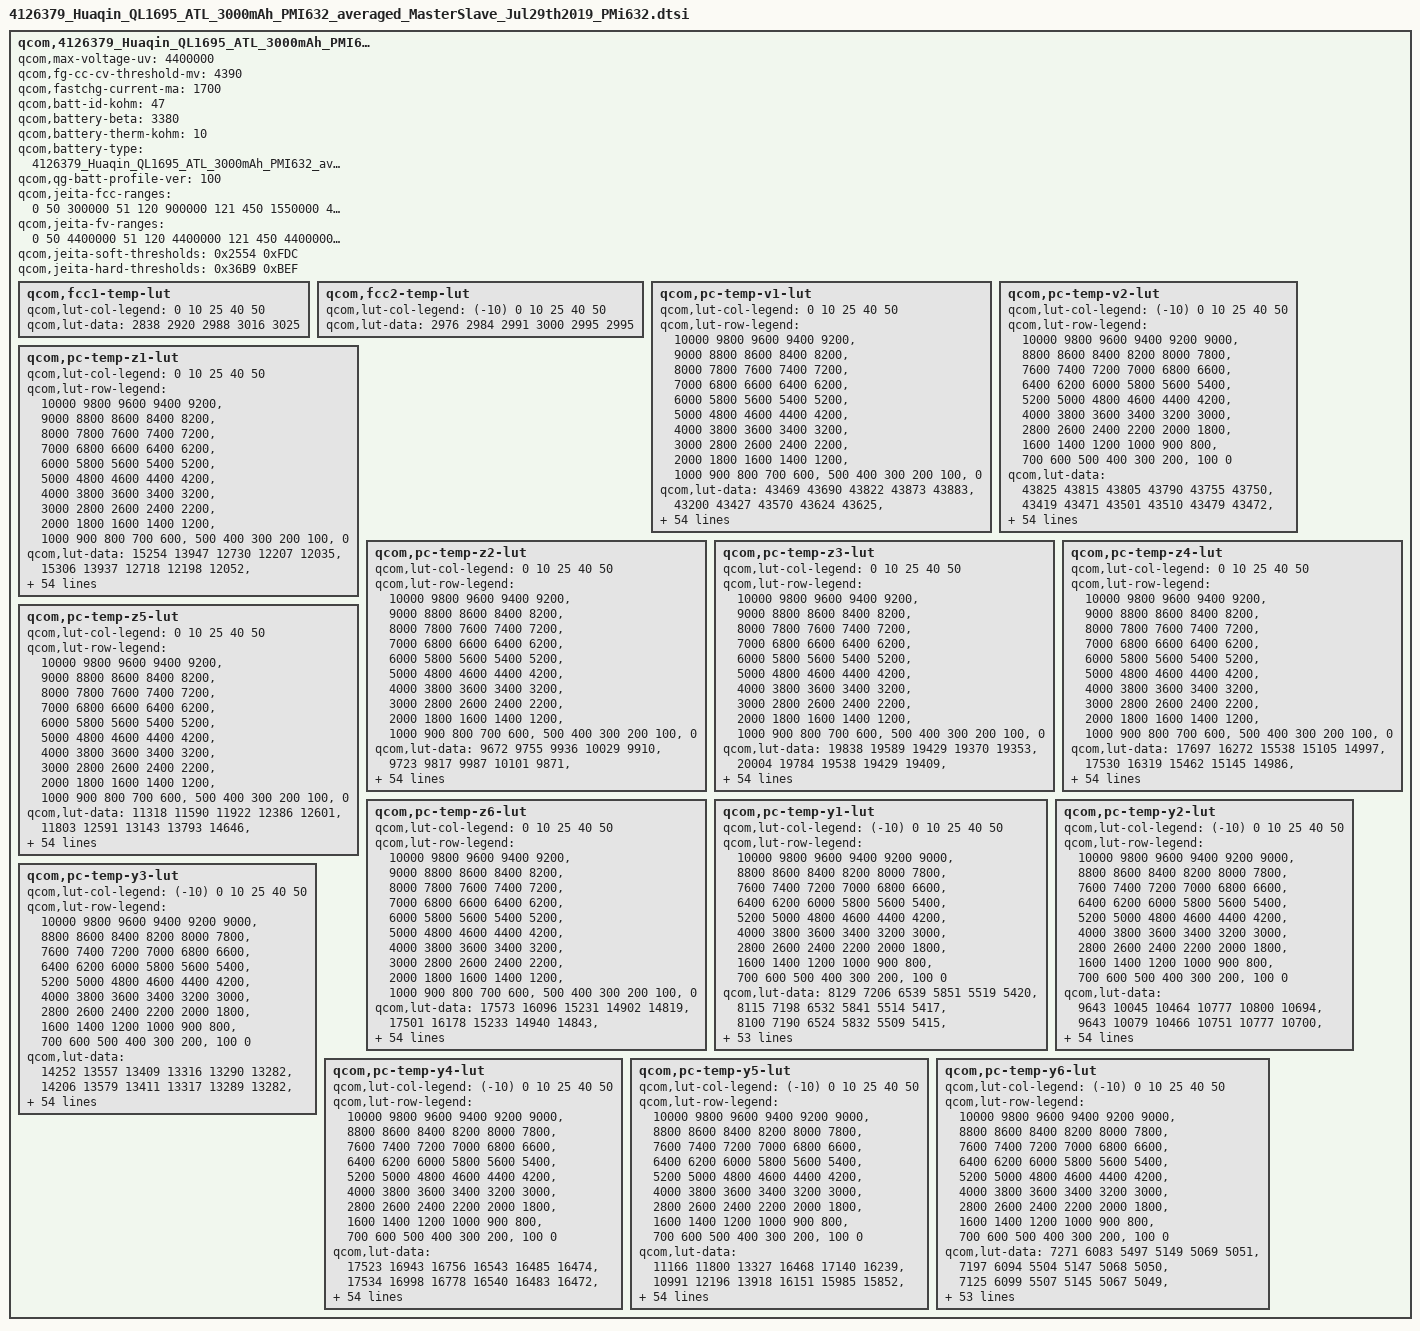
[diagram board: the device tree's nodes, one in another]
qcom,4126379_Huaqin_QL1695_ATL_3000mAh_PMI632 {
	/* 4126379_Huaqin_QL1695_ATL_3000mAh_PMI632_averaged_MasterSlave_Jul29th2019 */
	qcom,max-voltage-uv = <4400000>;
	qcom,fg-cc-cv-threshold-mv = <4390>;
	qcom,fastchg-current-ma = <1700>;
	qcom,batt-id-kohm = <47>;
	qcom,battery-beta = <3380>;
	qcom,battery-therm-kohm = <10>;
	qcom,battery-type = "4126379_Huaqin_QL1695_ATL_3000mAh_PMI632_averaged_MasterSlave_Jul29th2019";
	qcom,qg-batt-profile-ver = <100>;

	qcom,jeita-fcc-ranges = <0   50   300000
				 51   120   900000
				 121 450  1550000
				 451 550  1550000>;
	qcom,jeita-fv-ranges =  <0   50  4400000
				 51   120  4400000
				 121 450  4400000
				 451 550  4200000>;

	/* COOL = 15 DegC, WARM = 45 DegC */
	qcom,jeita-soft-thresholds = <0x2554 0xFDC>;
	/* COLD = 0 DegC, HOT = 55 DegC */
	qcom,jeita-hard-thresholds = <0x36B9 0xBEF>;

	qcom,fcc1-temp-lut {
		qcom,lut-col-legend = <0 10 25 40 50>;
		qcom,lut-data = <2838 2920 2988 3016 3025>;
	};

	qcom,fcc2-temp-lut {
		qcom,lut-col-legend = <(-10) 0 10 25 40 50>;
		qcom,lut-data = <2976 2984 2991 3000 2995 2995>;
	};

	qcom,pc-temp-v1-lut {
		qcom,lut-col-legend = <0 10 25 40 50>;
		qcom,lut-row-legend = <10000 9800 9600 9400 9200>,
			<9000 8800 8600 8400 8200>,
			<8000 7800 7600 7400 7200>,
			<7000 6800 6600 6400 6200>,
			<6000 5800 5600 5400 5200>,
			<5000 4800 4600 4400 4200>,
			<4000 3800 3600 3400 3200>,
			<3000 2800 2600 2400 2200>,
			<2000 1800 1600 1400 1200>,
			<1000 900 800 700 600>,
			<500 400 300 200 100>,
			<0>;
		qcom,lut-data = <43469 43690 43822 43873 43883>,
			<43200 43427 43570 43624 43625>,
			<42942 43177 43321 43378 43385>,
			<42697 42936 43077 43137 43148>,
			<42463 42697 42835 42899 42911>,
			<42236 42458 42595 42662 42676>,
			<42014 42223 42356 42425 42442>,
			<41798 41994 42120 42187 42209>,
			<41589 41770 41888 41954 41978>,
			<41388 41551 41661 41724 41746>,
			<41190 41338 41436 41497 41517>,
			<40993 41130 41217 41275 41295>,
			<40797 40930 41002 41055 41075>,
			<40596 40739 40796 40845 40864>,
			<40363 40545 40595 40640 40657>,
			<40126 40336 40402 40444 40458>,
			<39946 40128 40214 40254 40266>,
			<39816 39954 40035 40073 40083>,
			<39698 39815 39873 39902 39909>,
			<39567 39680 39729 39748 39753>,
			<39432 39532 39567 39588 39594>,
			<39299 39375 39354 39391 39401>,
			<39169 39201 39131 39171 39185>,
			<39043 38977 38954 38982 38993>,
			<38919 38771 38800 38819 38828>,
			<38795 38652 38672 38678 38683>,
			<38679 38568 38566 38563 38562>,
			<38575 38498 38474 38464 38458>,
			<38479 38437 38392 38373 38364>,
			<38405 38382 38319 38288 38277>,
			<38354 38330 38254 38213 38199>,
			<38313 38280 38196 38145 38127>,
			<38277 38236 38145 38085 38061>,
			<38246 38202 38100 38033 38004>,
			<38219 38173 38062 37991 37957>,
			<38193 38142 38025 37949 37909>,
			<38168 38113 37989 37902 37848>,
			<38134 38076 37951 37850 37779>,
			<38077 38014 37894 37785 37703>,
			<38000 37924 37807 37703 37624>,
			<37908 37823 37706 37608 37533>,
			<37787 37708 37593 37496 37422>,
			<37651 37572 37462 37366 37293>,
			<37497 37402 37301 37207 37135>,
			<37342 37251 37154 37065 36996>,
			<37233 37152 37058 36975 36910>,
			<37196 37121 37036 36951 36887>,
			<37167 37100 37017 36934 36873>,
			<37138 37078 36997 36919 36855>,
			<37081 37031 36953 36867 36791>,
			<36869 36807 36708 36594 36497>,
			<36418 36360 36271 36155 36054>,
			<35843 35785 35696 35578 35476>,
			<35064 35000 34911 34788 34682>,
			<33823 33761 33682 33554 33445>,
			<30000 30000 30000 30000 30000>;
	};

	qcom,pc-temp-v2-lut {
		qcom,lut-col-legend = <(-10) 0 10 25 40 50>;
		qcom,lut-row-legend = <10000 9800 9600 9400 9200 9000>,
			<8800 8600 8400 8200 8000 7800>,
			<7600 7400 7200 7000 6800 6600>,
			<6400 6200 6000 5800 5600 5400>,
			<5200 5000 4800 4600 4400 4200>,
			<4000 3800 3600 3400 3200 3000>,
			<2800 2600 2400 2200 2000 1800>,
			<1600 1400 1200 1000 900 800>,
			<700 600 500 400 300 200>,
			<100 0>;
		qcom,lut-data = <43825 43815 43805 43790 43755 43750>,
			<43419 43471 43501 43510 43479 43472>,
			<43056 43155 43215 43242 43214 43207>,
			<42740 42871 42950 42988 42963 42957>,
			<42461 42618 42704 42748 42726 42720>,
			<42214 42372 42464 42512 42492 42488>,
			<42006 42123 42221 42276 42259 42254>,
			<41813 41878 41981 42041 42026 42021>,
			<41584 41631 41749 41811 41797 41792>,
			<41299 41375 41523 41583 41570 41566>,
			<41050 41152 41304 41359 41346 41343>,
			<40904 40998 41096 41140 41126 41125>,
			<40783 40861 40895 40924 40910 40911>,
			<40565 40655 40694 40716 40704 40704>,
			<40123 40326 40493 40512 40502 40500>,
			<39712 40011 40287 40315 40309 40305>,
			<39493 39793 40066 40127 40122 40119>,
			<39328 39607 39841 39944 39943 39941>,
			<39158 39418 39626 39762 39770 39769>,
			<38982 39227 39418 39582 39610 39609>,
			<38816 39044 39222 39394 39436 39437>,
			<38659 38873 39038 39172 39214 39217>,
			<38514 38711 38867 38946 38977 38984>,
			<38395 38555 38714 38773 38793 38799>,
			<38296 38399 38578 38632 38643 38645>,
			<38213 38266 38454 38509 38516 38515>,
			<38144 38167 38340 38399 38405 38405>,
			<38084 38086 38235 38300 38307 38308>,
			<38026 38022 38137 38210 38218 38217>,
			<37968 37973 38043 38126 38136 38132>,
			<37911 37929 37963 38051 38062 38055>,
			<37856 37885 37898 37981 37994 37987>,
			<37802 37843 37845 37917 37933 37923>,
			<37744 37798 37800 37857 37868 37857>,
			<37684 37749 37764 37802 37802 37791>,
			<37622 37697 37728 37745 37730 37714>,
			<37558 37643 37688 37682 37641 37610>,
			<37493 37585 37646 37615 37544 37491>,
			<37426 37520 37591 37545 37458 37394>,
			<37359 37447 37520 37471 37383 37316>,
			<37293 37365 37435 37389 37303 37235>,
			<37229 37269 37331 37289 37206 37138>,
			<37166 37159 37211 37173 37094 37027>,
			<37096 37049 37087 37030 36952 36884>,
			<37016 36945 36959 36912 36846 36782>,
			<36917 36850 36856 36860 36802 36742>,
			<36857 36802 36828 36842 36788 36732>,
			<36786 36750 36791 36821 36770 36717>,
			<36693 36687 36739 36784 36740 36682>,
			<36555 36592 36651 36689 36637 36551>,
			<36322 36367 36389 36364 36296 36188>,
			<35934 35924 35914 35860 35792 35680>,
			<35343 35280 35269 35198 35138 35009>,
			<34432 34337 34374 34286 34224 34091>,
			<32920 32927 33035 32916 32950 32792>,
			<28595 28182 27887 28019 27977 27965>;
	};

	qcom,pc-temp-z1-lut {
		qcom,lut-col-legend = <0 10 25 40 50>;
		qcom,lut-row-legend = <10000 9800 9600 9400 9200>,
			<9000 8800 8600 8400 8200>,
			<8000 7800 7600 7400 7200>,
			<7000 6800 6600 6400 6200>,
			<6000 5800 5600 5400 5200>,
			<5000 4800 4600 4400 4200>,
			<4000 3800 3600 3400 3200>,
			<3000 2800 2600 2400 2200>,
			<2000 1800 1600 1400 1200>,
			<1000 900 800 700 600>,
			<500 400 300 200 100>,
			<0>;
		qcom,lut-data = <15254 13947 12730 12207 12035>,
			<15306 13937 12718 12198 12052>,
			<15331 13909 12706 12192 12046>,
			<15316 13856 12694 12188 12043>,
			<15233 13830 12680 12184 12039>,
			<15163 13827 12670 12180 12036>,
			<15144 13826 12662 12176 12035>,
			<15133 13826 12657 12173 12034>,
			<15132 13827 12651 12171 12033>,
			<15149 13828 12645 12168 12031>,
			<15168 13828 12641 12166 12029>,
			<15161 13828 12638 12165 12029>,
			<15125 13823 12635 12163 12030>,
			<15095 13800 12630 12163 12030>,
			<15083 13778 12620 12162 12030>,
			<15075 13768 12615 12162 12030>,
			<15074 13761 12615 12162 12029>,
			<15094 13756 12617 12162 12028>,
			<15120 13753 12619 12163 12028>,
			<15143 13755 12622 12163 12030>,
			<15167 13771 12624 12164 12032>,
			<15180 13800 12627 12165 12036>,
			<15183 13818 12631 12169 12040>,
			<15186 13827 12636 12173 12044>,
			<15191 13834 12643 12178 12049>,
			<15206 13840 12650 12182 12053>,
			<15222 13845 12658 12187 12056>,
			<15231 13849 12665 12192 12058>,
			<15239 13852 12672 12197 12061>,
			<15246 13857 12679 12202 12066>,
			<15253 13861 12685 12207 12070>,
			<15260 13865 12690 12211 12073>,
			<15268 13870 12694 12215 12076>,
			<15277 13877 12700 12218 12079>,
			<15287 13885 12708 12222 12083>,
			<15299 13894 12715 12226 12088>,
			<15313 13905 12722 12232 12092>,
			<15322 13915 12729 12239 12097>,
			<15331 13921 12736 12244 12101>,
			<15337 13927 12743 12248 12104>,
			<15336 13934 12750 12252 12107>,
			<15331 13941 12758 12256 12111>,
			<15332 13948 12765 12261 12114>,
			<15335 13955 12767 12263 12116>,
			<15330 13958 12774 12266 12117>,
			<15323 13958 12777 12269 12118>,
			<15317 13956 12779 12272 12119>,
			<15314 13955 12781 12272 12120>,
			<15316 13957 12788 12276 12125>,
			<15327 13972 12796 12284 12130>,
			<15355 13994 12811 12294 12139>,
			<15391 14028 12833 12308 12146>,
			<15417 14065 12860 12326 12165>,
			<15482 14134 12903 12351 12184>,
			<15482 14134 12903 12351 12184>,
			<15482 14134 12903 12351 12184>;
	};

	qcom,pc-temp-z2-lut {
		qcom,lut-col-legend = <0 10 25 40 50>;
		qcom,lut-row-legend = <10000 9800 9600 9400 9200>,
			<9000 8800 8600 8400 8200>,
			<8000 7800 7600 7400 7200>,
			<7000 6800 6600 6400 6200>,
			<6000 5800 5600 5400 5200>,
			<5000 4800 4600 4400 4200>,
			<4000 3800 3600 3400 3200>,
			<3000 2800 2600 2400 2200>,
			<2000 1800 1600 1400 1200>,
			<1000 900 800 700 600>,
			<500 400 300 200 100>,
			<0>;
		qcom,lut-data = <9672 9755 9936 10029 9910>,
			<9723 9817 9987 10101 9871>,
			<9759 9819 10018 10117 10012>,
			<9773 9812 10021 10120 10086>,
			<9782 9808 10018 10114 10091>,
			<9788 9806 10017 10106 10084>,
			<9790 9805 10018 10111 10057>,
			<9792 9806 10019 10125 9996>,
			<9791 9813 10024 10130 9967>,
			<9783 9819 10035 10114 9978>,
			<9770 9821 10041 10093 9992>,
			<9756 9825 10039 10070 10000>,
			<9737 9845 10037 10038 10007>,
			<9721 9913 10037 10028 10010>,
			<9708 9958 10038 10036 10013>,
			<9697 9962 10038 10046 10018>,
			<9697 9963 10038 10048 10027>,
			<9715 9960 10037 10045 10045>,
			<9734 9927 10036 10041 10055>,
			<9738 9897 10035 10034 10065>,
			<9740 9891 10034 10028 10072>,
			<9741 9884 10031 10052 10074>,
			<9742 9875 10027 10104 10074>,
			<9744 9857 10032 10124 10061>,
			<9746 9842 10052 10125 10001>,
			<9750 9844 10064 10119 9946>,
			<9754 9856 10040 10095 9938>,
			<9759 9863 10007 10056 9934>,
			<9764 9863 9996 10030 9936>,
			<9770 9862 9991 10010 9946>,
			<9776 9863 9989 10000 9957>,
			<9783 9867 9992 10008 9963>,
			<9790 9870 9998 10022 9969>,
			<9799 9876 10007 10025 9979>,
			<9808 9886 10029 10017 10004>,
			<9819 9895 10048 10011 10035>,
			<9831 9905 10056 10029 10075>,
			<9843 9915 10063 10068 10120>,
			<9855 9927 10079 10095 10129>,
			<9864 9940 10113 10118 10117>,
			<9834 9946 10132 10132 10108>,
			<9723 9950 10127 10134 10126>,
			<10252 9950 10122 10134 10149>,
			<12743 9947 10132 10144 10104>,
			<13411 9957 10142 10159 10087>,
			<12477 9972 10128 10184 10106>,
			<13615 9977 10121 10125 10082>,
			<13747 10046 10095 10118 10135>,
			<13794 10166 10097 10133 10127>,
			<13736 10176 10124 10212 10179>,
			<13116 10149 10210 10169 10012>,
			<12466 10089 10150 10108 9951>,
			<11791 10061 10115 10037 9917>,
			<10733 9999 10046 9980 9847>,
			<10733 9999 10046 9980 9847>,
			<10733 9999 10046 9980 9847>;
	};

	qcom,pc-temp-z3-lut {
		qcom,lut-col-legend = <0 10 25 40 50>;
		qcom,lut-row-legend = <10000 9800 9600 9400 9200>,
			<9000 8800 8600 8400 8200>,
			<8000 7800 7600 7400 7200>,
			<7000 6800 6600 6400 6200>,
			<6000 5800 5600 5400 5200>,
			<5000 4800 4600 4400 4200>,
			<4000 3800 3600 3400 3200>,
			<3000 2800 2600 2400 2200>,
			<2000 1800 1600 1400 1200>,
			<1000 900 800 700 600>,
			<500 400 300 200 100>,
			<0>;
		qcom,lut-data = <19838 19589 19429 19370 19353>,
			<20004 19784 19538 19429 19409>,
			<20098 19849 19603 19470 19420>,
			<20095 19887 19604 19482 19424>,
			<20023 19897 19592 19469 19421>,
			<19963 19881 19580 19453 19417>,
			<19947 19855 19568 19447 19410>,
			<19938 19832 19554 19444 19399>,
			<19936 19807 19541 19440 19393>,
			<19952 19789 19528 19430 19391>,
			<19972 19778 19521 19420 19390>,
			<19975 19769 19519 19415 19387>,
			<19966 19755 19516 19410 19381>,
			<19962 19731 19508 19404 19377>,
			<19974 19714 19491 19394 19373>,
			<19989 19712 19481 19387 19369>,
			<19987 19710 19479 19386 19368>,
			<19922 19705 19479 19386 19367>,
			<19859 19680 19477 19385 19366>,
			<19856 19659 19467 19383 19358>,
			<19866 19664 19462 19382 19350>,
			<19878 19681 19484 19387 19356>,
			<19894 19698 19513 19400 19375>,
			<19914 19718 19516 19414 19388>,
			<19932 19734 19511 19433 19396>,
			<19951 19735 19508 19445 19401>,
			<19966 19731 19521 19441 19403>,
			<19972 19729 19539 19433 19404>,
			<19975 19725 19540 19428 19403>,
			<19975 19721 19533 19426 19394>,
			<19961 19720 19525 19424 19384>,
			<19940 19719 19519 19421 19381>,
			<19923 19717 19512 19417 19379>,
			<19906 19706 19507 19412 19376>,
			<19889 19687 19500 19407 19370>,
			<19868 19677 19495 19402 19366>,
			<19844 19673 19489 19396 19365>,
			<19826 19669 19483 19390 19365>,
			<19817 19664 19478 19386 19365>,
			<19805 19657 19472 19383 19366>,
			<19742 19649 19468 19382 19366>,
			<19570 19634 19465 19383 19362>,
			<19469 19624 19462 19384 19358>,
			<19264 19620 19457 19384 19359>,
			<19257 19603 19450 19380 19362>,
			<19258 19577 19447 19373 19360>,
			<19257 19573 19431 19370 19357>,
			<19257 19516 19428 19372 19343>,
			<19257 19445 19428 19354 19339>,
			<19257 19459 19417 19347 19337>,
			<19257 19471 19398 19356 19362>,
			<19257 19490 19398 19363 19369>,
			<19257 19462 19402 19370 19371>,
			<19259 19444 19406 19378 19382>,
			<19259 19444 19406 19378 19382>,
			<19259 19444 19406 19378 19382>;
	};

	qcom,pc-temp-z4-lut {
		qcom,lut-col-legend = <0 10 25 40 50>;
		qcom,lut-row-legend = <10000 9800 9600 9400 9200>,
			<9000 8800 8600 8400 8200>,
			<8000 7800 7600 7400 7200>,
			<7000 6800 6600 6400 6200>,
			<6000 5800 5600 5400 5200>,
			<5000 4800 4600 4400 4200>,
			<4000 3800 3600 3400 3200>,
			<3000 2800 2600 2400 2200>,
			<2000 1800 1600 1400 1200>,
			<1000 900 800 700 600>,
			<500 400 300 200 100>,
			<0>;
		qcom,lut-data = <17697 16272 15538 15105 14997>,
			<17530 16319 15462 15145 14986>,
			<17330 16196 15376 15068 14948>,
			<17093 15853 15272 15009 14918>,
			<16802 15585 15149 14974 14905>,
			<16520 15409 15072 14947 14895>,
			<16264 15279 15036 14926 14885>,
			<16026 15209 15011 14909 14875>,
			<15854 15164 14985 14893 14864>,
			<15739 15130 14962 14879 14851>,
			<15644 15104 14940 14866 14837>,
			<15547 15081 14917 14852 14825>,
			<15454 15050 14897 14839 14812>,
			<15381 15009 14884 14826 14800>,
			<15331 14976 14875 14814 14788>,
			<15292 14954 14864 14801 14775>,
			<15263 14939 14841 14786 14761>,
			<15239 14927 14818 14769 14745>,
			<15216 14913 14805 14756 14734>,
			<15186 14902 14795 14743 14725>,
			<15149 14904 14793 14736 14720>,
			<15119 14915 14896 14796 14758>,
			<15096 14941 15039 14931 14863>,
			<15079 15117 15083 14971 14902>,
			<15077 15297 15103 14957 14898>,
			<15093 15299 15105 14937 14890>,
			<15115 15238 15056 14915 14875>,
			<15139 15174 14984 14889 14850>,
			<15170 15113 14945 14866 14829>,
			<15182 15055 14918 14845 14815>,
			<15167 15018 14898 14827 14801>,
			<15139 14991 14883 14812 14787>,
			<15113 14970 14870 14800 14773>,
			<15086 14952 14860 14790 14761>,
			<15061 14937 14850 14781 14751>,
			<15040 14924 14846 14777 14745>,
			<15021 14911 14848 14791 14764>,
			<15006 14903 14853 14817 14802>,
			<14994 14910 14861 14828 14812>,
			<14985 14925 14879 14831 14805>,
			<15033 14929 14889 14832 14796>,
			<15205 14902 14868 14818 14784>,
			<15292 14887 14849 14801 14775>,
			<15484 14886 14849 14810 14785>,
			<15425 14859 14836 14808 14784>,
			<15400 14832 14803 14788 14763>,
			<15384 14814 14776 14765 14744>,
			<15364 14839 14741 14726 14718>,
			<15342 14896 14709 14701 14685>,
			<15328 14871 14718 14709 14692>,
			<15333 14888 14787 14746 14710>,
			<15390 14888 14792 14742 14707>,
			<15421 14934 14789 14736 14705>,
			<15464 14973 14791 14729 14697>,
			<15464 14973 14791 14729 14697>,
			<15464 14973 14791 14729 14697>;
	};

	qcom,pc-temp-z5-lut {
		qcom,lut-col-legend = <0 10 25 40 50>;
		qcom,lut-row-legend = <10000 9800 9600 9400 9200>,
			<9000 8800 8600 8400 8200>,
			<8000 7800 7600 7400 7200>,
			<7000 6800 6600 6400 6200>,
			<6000 5800 5600 5400 5200>,
			<5000 4800 4600 4400 4200>,
			<4000 3800 3600 3400 3200>,
			<3000 2800 2600 2400 2200>,
			<2000 1800 1600 1400 1200>,
			<1000 900 800 700 600>,
			<500 400 300 200 100>,
			<0>;
		qcom,lut-data = <11318 11590 11922 12386 12601>,
			<11803 12591 13143 13793 14646>,
			<12155 13121 14060 15155 15632>,
			<12300 13485 14621 15607 16047>,
			<12369 13875 15073 15573 16143>,
			<12440 14401 15268 15534 16192>,
			<12572 14836 15300 15619 16085>,
			<12736 14969 15307 15841 15658>,
			<12835 15010 15281 15910 15441>,
			<12904 15039 15215 15676 15606>,
			<12961 15209 15226 15448 15844>,
			<13004 15432 15536 15463 15923>,
			<13083 15454 15874 15526 15863>,
			<13194 15349 15780 15528 15810>,
			<13524 15281 15314 15261 15787>,
			<13976 15488 15085 15010 15846>,
			<14060 15889 15614 15176 16243>,
			<13636 16087 16392 15695 17009>,
			<13233 16146 16708 16229 17292>,
			<13323 16224 16822 16885 17053>,
			<13818 16976 17151 17317 16654>,
			<14449 18706 19014 17040 16184>,
			<15215 19952 21151 16273 15553>,
			<16177 20807 20461 15672 15024>,
			<17273 21341 16646 15034 14486>,
			<18743 20826 14580 14631 14138>,
			<19949 18980 15053 14673 14367>,
			<20501 17927 15876 14827 14974>,
			<20949 17820 16513 15065 15248>,
			<21056 17819 17085 15597 15273>,
			<20405 18178 17703 16287 15309>,
			<19421 19513 18478 17062 15676>,
			<18804 20420 19337 17959 16477>,
			<18392 20339 20206 18828 17260>,
			<17993 20146 21208 19814 18174>,
			<17428 20225 21675 20369 18734>,
			<16772 20856 21631 19935 18513>,
			<16452 21391 21506 18944 17988>,
			<16505 21407 21117 18127 17675>,
			<16570 21263 19920 17331 17528>,
			<15918 20974 19181 16909 17351>,
			<13986 19805 19185 17072 16936>,
			<12855 18984 19176 17266 16384>,
			<10711 18645 18116 16693 15817>,
			<10625 18123 17719 15833 15743>,
			<10620 16755 18000 15447 15466>,
			<10598 16711 16868 15757 15628>,
			<10575 14187 17708 17275 15327>,
			<10565 12442 18906 16779 17274>,
			<10574 12665 17661 15688 16200>,
			<10598 12881 13950 13714 15616>,
			<10582 13118 13556 13748 15642>,
			<10548 12482 13449 13886 15362>,
			<10490 11908 13298 13974 16006>,
			<10490 11908 13298 13974 16006>,
			<10490 11908 13298 13974 16006>;
	};

	qcom,pc-temp-z6-lut {
		qcom,lut-col-legend = <0 10 25 40 50>;
		qcom,lut-row-legend = <10000 9800 9600 9400 9200>,
			<9000 8800 8600 8400 8200>,
			<8000 7800 7600 7400 7200>,
			<7000 6800 6600 6400 6200>,
			<6000 5800 5600 5400 5200>,
			<5000 4800 4600 4400 4200>,
			<4000 3800 3600 3400 3200>,
			<3000 2800 2600 2400 2200>,
			<2000 1800 1600 1400 1200>,
			<1000 900 800 700 600>,
			<500 400 300 200 100>,
			<0>;
		qcom,lut-data = <17573 16096 15231 14902 14819>,
			<17501 16178 15233 14940 14843>,
			<17393 16125 15230 14930 14832>,
			<17246 15966 15205 14918 14821>,
			<17030 15832 15136 14896 14814>,
			<16825 15730 15085 14872 14806>,
			<16665 15647 15060 14859 14798>,
			<16526 15596 15041 14849 14787>,
			<16444 15559 15021 14839 14778>,
			<16403 15532 15003 14827 14771>,
			<16370 15514 14988 14816 14765>,
			<16322 15498 14977 14806 14757>,
			<16258 15472 14966 14798 14749>,
			<16211 15431 14953 14789 14741>,
			<16192 15400 14939 14778 14733>,
			<16178 15388 14927 14768 14725>,
			<16158 15380 14916 14760 14718>,
			<16126 15370 14907 14753 14712>,
			<16099 15355 14899 14747 14705>,
			<16093 15346 14891 14741 14698>,
			<16089 15350 14889 14737 14692>,
			<16088 15366 14945 14767 14712>,
			<16092 15393 15023 14834 14769>,
			<16101 15484 15045 14859 14794>,
			<16113 15571 15054 14862 14797>,
			<16135 15574 15056 14863 14799>,
			<16159 15551 15043 14856 14795>,
			<16181 15527 15022 14839 14785>,
			<16203 15503 15007 14826 14774>,
			<16211 15479 14993 14816 14763>,
			<16203 15466 14981 14807 14753>,
			<16188 15458 14972 14799 14745>,
			<16175 15449 14964 14792 14738>,
			<16162 15437 14957 14786 14732>,
			<16150 15425 14951 14778 14724>,
			<16139 15420 14948 14774 14719>,
			<16127 15419 14948 14779 14727>,
			<16124 15418 14948 14787 14744>,
			<16125 15423 14951 14790 14748>,
			<16128 15434 14957 14791 14746>,
			<16131 15437 14961 14792 14743>,
			<16131 15426 14953 14786 14736>,
			<16131 15421 14944 14780 14730>,
			<16132 15428 14944 14785 14737>,
			<16118 15417 14936 14783 14737>,
			<16118 15399 14923 14771 14727>,
			<16114 15391 14903 14759 14718>,
			<16110 15380 14888 14744 14700>,
			<16110 15373 14876 14724 14683>,
			<16118 15380 14877 14726 14686>,
			<16145 15407 14902 14748 14710>,
			<16195 15432 14910 14754 14715>,
			<16247 15459 14918 14759 14719>,
			<16325 15500 14932 14765 14726>,
			<16325 15500 14932 14765 14726>,
			<16325 15500 14932 14765 14726>;
	};

	qcom,pc-temp-y1-lut {
		qcom,lut-col-legend = <(-10) 0 10 25 40 50>;
		qcom,lut-row-legend = <10000 9800 9600 9400 9200 9000>,
			<8800 8600 8400 8200 8000 7800>,
			<7600 7400 7200 7000 6800 6600>,
			<6400 6200 6000 5800 5600 5400>,
			<5200 5000 4800 4600 4400 4200>,
			<4000 3800 3600 3400 3200 3000>,
			<2800 2600 2400 2200 2000 1800>,
			<1600 1400 1200 1000 900 800>,
			<700 600 500 400 300 200>,
			<100 0>;
		qcom,lut-data = <8129 7206 6539 5851 5519 5420>,
			<8115 7198 6532 5841 5514 5417>,
			<8100 7190 6524 5832 5509 5415>,
			<8085 7182 6516 5824 5504 5413>,
			<8072 7176 6509 5816 5500 5411>,
			<8062 7171 6503 5808 5497 5409>,
			<8056 7167 6498 5801 5494 5408>,
			<8051 7164 6494 5794 5492 5406>,
			<8047 7158 6488 5788 5489 5405>,
			<8044 7146 6480 5783 5485 5403>,
			<8042 7138 6472 5778 5482 5402>,
			<8042 7138 6465 5773 5482 5402>,
			<8043 7139 6458 5768 5481 5402>,
			<8046 7142 6453 5763 5480 5402>,
			<8059 7155 6450 5758 5479 5401>,
			<8070 7166 6448 5755 5477 5401>,
			<8068 7164 6453 5754 5477 5401>,
			<8064 7158 6461 5754 5476 5401>,
			<8060 7156 6463 5754 5476 5401>,
			<8048 7153 6460 5752 5477 5401>,
			<8035 7151 6457 5751 5477 5401>,
			<8029 7154 6456 5752 5478 5402>,
			<8024 7160 6455 5754 5479 5404>,
			<8018 7160 6455 5756 5480 5405>,
			<8011 7153 6457 5758 5482 5406>,
			<8004 7145 6459 5761 5484 5407>,
			<7998 7141 6462 5763 5486 5409>,
			<7992 7137 6465 5766 5488 5411>,
			<7986 7133 6468 5769 5491 5414>,
			<7979 7129 6469 5772 5495 5416>,
			<7971 7125 6471 5776 5499 5418>,
			<7965 7121 6473 5782 5502 5421>,
			<7960 7118 6475 5789 5505 5424>,
			<7955 7115 6477 5795 5509 5426>,
			<7949 7110 6478 5800 5512 5428>,
			<7944 7106 6480 5804 5515 5430>,
			<7937 7101 6482 5808 5517 5431>,
			<7929 7096 6484 5812 5519 5433>,
			<7920 7090 6487 5816 5521 5435>,
			<7910 7084 6490 5820 5523 5437>,
			<7901 7078 6493 5825 5525 5439>,
			<7893 7072 6494 5832 5529 5442>,
			<7888 7068 6495 5840 5533 5444>,
			<7888 7069 6497 5849 5536 5447>,
			<7894 7073 6499 5861 5541 5451>,
			<7959 7113 6519 5871 5549 5456>,
			<8020 7134 6524 5877 5551 5457>,
			<8028 7135 6525 5882 5553 5458>,
			<8030 7136 6526 5889 5554 5457>,
			<8030 7138 6527 5896 5555 5459>,
			<8033 7142 6532 5900 5559 5463>,
			<8037 7164 6541 5922 5569 5470>,
			<8039 7187 6559 5952 5584 5480>,
			<8054 7211 6596 5990 5603 5495>,
			<8054 7211 6596 5990 5603 5495>,
			<8054 7211 6596 5990 5603 5495>;
	};

	qcom,pc-temp-y2-lut {
		qcom,lut-col-legend = <(-10) 0 10 25 40 50>;
		qcom,lut-row-legend = <10000 9800 9600 9400 9200 9000>,
			<8800 8600 8400 8200 8000 7800>,
			<7600 7400 7200 7000 6800 6600>,
			<6400 6200 6000 5800 5600 5400>,
			<5200 5000 4800 4600 4400 4200>,
			<4000 3800 3600 3400 3200 3000>,
			<2800 2600 2400 2200 2000 1800>,
			<1600 1400 1200 1000 900 800>,
			<700 600 500 400 300 200>,
			<100 0>;
		qcom,lut-data = <9643 10045 10464 10777 10800 10694>,
			<9643 10079 10466 10751 10777 10700>,
			<9643 10123 10466 10727 10744 10696>,
			<9748 10167 10464 10704 10709 10685>,
			<9890 10201 10462 10683 10680 10668>,
			<9996 10215 10459 10666 10663 10648>,
			<10065 10210 10453 10649 10654 10617>,
			<10119 10201 10444 10636 10648 10585>,
			<10183 10209 10444 10632 10646 10573>,
			<10268 10276 10449 10632 10645 10569>,
			<10316 10336 10456 10632 10645 10567>,
			<10300 10360 10462 10640 10648 10576>,
			<10268 10380 10470 10655 10655 10593>,
			<10236 10396 10488 10671 10665 10596>,
			<10126 10416 10536 10692 10685 10595>,
			<10038 10436 10572 10714 10713 10600>,
			<9935 10453 10580 10737 10749 10640>,
			<9748 10470 10584 10760 10796 10709>,
			<9690 10483 10583 10782 10849 10774>,
			<9684 10496 10573 10806 10918 10852>,
			<9678 10505 10566 10818 10956 10894>,
			<9673 10507 10579 10803 10898 10856>,
			<9668 10507 10605 10779 10803 10791>,
			<9666 10505 10620 10775 10777 10771>,
			<9665 10500 10631 10781 10777 10767>,
			<9664 10496 10638 10790 10783 10770>,
			<9664 10499 10641 10805 10800 10803>,
			<9663 10507 10644 10823 10824 10853>,
			<9662 10505 10647 10836 10839 10871>,
			<9661 10491 10650 10846 10856 10871>,
			<9660 10463 10654 10855 10868 10874>,
			<9659 10257 10657 10867 10901 10896>,
			<9659 9860 10661 10878 10952 10920>,
			<9658 9712 10660 10880 10964 10926>,
			<9657 9685 10647 10876 10960 10938>,
			<9656 9672 10629 10872 10950 10940>,
			<9656 9667 10615 10861 10921 10912>,
			<9655 9664 10599 10846 10883 10870>,
			<9655 9662 10578 10839 10869 10841>,
			<9655 9660 10545 10836 10862 10818>,
			<9655 9658 10505 10832 10853 10803>,
			<9654 9657 10459 10822 10838 10796>,
			<9654 9656 10403 10805 10828 10794>,
			<9654 9655 10347 10767 10817 10807>,
			<9654 9654 10227 10703 10785 10779>,
			<9653 9653 10177 10693 10729 10686>,
			<9653 9653 10206 10687 10724 10630>,
			<9653 9653 10051 10699 10713 10684>,
			<9653 9652 9966 10678 10753 10664>,
			<9652 9652 9940 10677 10755 10596>,
			<9652 9652 9725 10628 10649 10587>,
			<9652 9652 9675 10582 10615 10534>,
			<9651 9651 9662 10510 10588 10471>,
			<9650 9651 9657 10464 10512 10385>,
			<9650 9651 9657 10464 10512 10385>,
			<9650 9651 9657 10464 10512 10385>;
	};

	qcom,pc-temp-y3-lut {
		qcom,lut-col-legend = <(-10) 0 10 25 40 50>;
		qcom,lut-row-legend = <10000 9800 9600 9400 9200 9000>,
			<8800 8600 8400 8200 8000 7800>,
			<7600 7400 7200 7000 6800 6600>,
			<6400 6200 6000 5800 5600 5400>,
			<5200 5000 4800 4600 4400 4200>,
			<4000 3800 3600 3400 3200 3000>,
			<2800 2600 2400 2200 2000 1800>,
			<1600 1400 1200 1000 900 800>,
			<700 600 500 400 300 200>,
			<100 0>;
		qcom,lut-data = <14252 13557 13409 13316 13290 13282>,
			<14206 13579 13411 13317 13289 13282>,
			<14102 13593 13416 13318 13289 13282>,
			<13979 13601 13422 13319 13289 13282>,
			<13875 13604 13426 13320 13290 13283>,
			<13829 13605 13428 13321 13292 13284>,
			<13829 13598 13428 13321 13295 13285>,
			<13831 13586 13428 13322 13298 13286>,
			<13813 13583 13428 13323 13300 13288>,
			<13693 13590 13426 13324 13301 13290>,
			<13605 13593 13425 13324 13302 13292>,
			<13606 13560 13425 13327 13302 13294>,
			<13609 13506 13425 13331 13302 13297>,
			<13607 13495 13424 13331 13303 13297>,
			<13582 13504 13418 13330 13307 13297>,
			<13559 13511 13412 13330 13309 13297>,
			<13554 13504 13408 13329 13309 13298>,
			<13550 13487 13405 13328 13309 13301>,
			<13548 13473 13400 13328 13309 13301>,
			<13545 13463 13391 13329 13308 13301>,
			<13542 13453 13384 13330 13305 13300>,
			<13532 13443 13379 13325 13301 13295>,
			<13514 13434 13376 13318 13295 13288>,
			<13495 13425 13372 13314 13292 13284>,
			<13474 13418 13369 13312 13289 13281>,
			<13461 13410 13367 13310 13288 13280>,
			<13473 13395 13364 13309 13288 13281>,
			<13508 13378 13361 13309 13288 13283>,
			<13537 13374 13359 13309 13287 13283>,
			<13558 13377 13356 13309 13287 13282>,
			<13581 13382 13354 13310 13288 13281>,
			<13614 13392 13352 13310 13289 13281>,
			<13658 13409 13351 13311 13290 13282>,
			<13703 13422 13352 13311 13290 13283>,
			<13749 13433 13354 13311 13290 13284>,
			<13797 13445 13358 13311 13290 13285>,
			<13849 13464 13361 13311 13289 13284>,
			<13904 13493 13364 13310 13287 13282>,
			<13959 13525 13367 13309 13286 13281>,
			<14011 13562 13370 13308 13286 13282>,
			<14066 13609 13372 13308 13286 13283>,
			<14131 13675 13374 13308 13287 13284>,
			<14205 13763 13377 13308 13288 13284>,
			<14288 13847 13385 13309 13286 13281>,
			<14383 13943 13392 13310 13287 13280>,
			<14460 13986 13396 13312 13291 13285>,
			<14448 14000 13406 13314 13293 13292>,
			<14553 14079 13423 13319 13298 13297>,
			<14650 14157 13446 13327 13306 13299>,
			<14772 14237 13474 13333 13307 13297>,
			<14915 14307 13504 13327 13299 13290>,
			<15097 14423 13551 13334 13301 13295>,
			<15352 14623 13653 13345 13308 13299>,
			<15956 14851 13876 13362 13313 13304>,
			<15956 14851 13876 13362 13313 13304>,
			<15956 14851 13876 13362 13313 13304>;
	};

	qcom,pc-temp-y4-lut {
		qcom,lut-col-legend = <(-10) 0 10 25 40 50>;
		qcom,lut-row-legend = <10000 9800 9600 9400 9200 9000>,
			<8800 8600 8400 8200 8000 7800>,
			<7600 7400 7200 7000 6800 6600>,
			<6400 6200 6000 5800 5600 5400>,
			<5200 5000 4800 4600 4400 4200>,
			<4000 3800 3600 3400 3200 3000>,
			<2800 2600 2400 2200 2000 1800>,
			<1600 1400 1200 1000 900 800>,
			<700 600 500 400 300 200>,
			<100 0>;
		qcom,lut-data = <17523 16943 16756 16543 16485 16474>,
			<17534 16998 16778 16540 16483 16472>,
			<17537 17074 16807 16539 16483 16471>,
			<17535 17154 16836 16539 16483 16471>,
			<17529 17220 16857 16540 16483 16470>,
			<17521 17257 16866 16542 16484 16470>,
			<17502 17269 16862 16547 16484 16472>,
			<17480 17277 16856 16554 16485 16475>,
			<17494 17271 16857 16561 16487 16478>,
			<17616 17233 16868 16571 16493 16481>,
			<17734 17205 16884 16582 16501 16485>,
			<17789 17343 16904 16591 16511 16488>,
			<17830 17579 16929 16602 16522 16493>,
			<17787 17593 16960 16618 16531 16501>,
			<17413 17313 17004 16645 16539 16512>,
			<17114 17083 17029 16675 16550 16524>,
			<17124 17048 16994 16712 16566 16534>,
			<17161 17028 16919 16745 16588 16545>,
			<17161 17000 16861 16750 16617 16563>,
			<17115 16957 16812 16743 16660 16598>,
			<17063 16908 16767 16731 16684 16619>,
			<17028 16862 16722 16664 16636 16589>,
			<16999 16814 16680 16568 16552 16533>,
			<16993 16761 16655 16535 16513 16503>,
			<17005 16691 16639 16522 16492 16484>,
			<17016 16648 16627 16517 16483 16476>,
			<17007 16656 16618 16521 16487 16478>,
			<16985 16676 16611 16528 16495 16483>,
			<16977 16686 16600 16535 16505 16490>,
			<16979 16689 16581 16544 16519 16504>,
			<16981 16693 16569 16555 16535 16520>,
			<16979 16717 16568 16567 16553 16537>,
			<16973 16764 16569 16579 16570 16553>,
			<16971 16797 16573 16586 16573 16558>,
			<16975 16819 16588 16590 16571 16559>,
			<16980 16837 16608 16592 16569 16560>,
			<16986 16848 16632 16579 16546 16538>,
			<16994 16856 16658 16559 16511 16501>,
			<17005 16868 16677 16548 16504 16493>,
			<17025 16902 16693 16542 16505 16493>,
			<17052 16930 16702 16539 16505 16493>,
			<17081 16916 16699 16541 16505 16493>,
			<17115 16885 16694 16543 16503 16491>,
			<17160 16891 16693 16536 16493 16478>,
			<17191 16913 16706 16528 16481 16471>,
			<17158 16905 16703 16526 16486 16479>,
			<17065 16895 16722 16547 16502 16493>,
			<17084 16937 16789 16577 16523 16521>,
			<17108 16998 16865 16616 16559 16562>,
			<17118 17053 16942 16647 16567 16546>,
			<17103 17042 16934 16587 16494 16481>,
			<17070 16977 16920 16584 16494 16482>,
			<17060 16961 16960 16627 16518 16496>,
			<17183 16977 17043 16729 16590 16583>,
			<17183 16977 17043 16729 16590 16583>,
			<17183 16977 17043 16729 16590 16583>;
	};

	qcom,pc-temp-y5-lut {
		qcom,lut-col-legend = <(-10) 0 10 25 40 50>;
		qcom,lut-row-legend = <10000 9800 9600 9400 9200 9000>,
			<8800 8600 8400 8200 8000 7800>,
			<7600 7400 7200 7000 6800 6600>,
			<6400 6200 6000 5800 5600 5400>,
			<5200 5000 4800 4600 4400 4200>,
			<4000 3800 3600 3400 3200 3000>,
			<2800 2600 2400 2200 2000 1800>,
			<1600 1400 1200 1000 900 800>,
			<700 600 500 400 300 200>,
			<100 0>;
		qcom,lut-data = <11166 11800 13327 16468 17140 16239>,
			<10991 12196 13918 16151 15985 15852>,
			<11198 12768 14405 15782 15254 15477>,
			<11717 13367 14773 15384 14837 15128>,
			<12479 13841 15006 14980 14629 14817>,
			<13416 14040 15089 14593 14523 14560>,
			<14932 13998 14997 14192 14739 14345>,
			<16529 13915 14796 13788 15116 14166>,
			<16499 13860 14587 13436 15041 14088>,
			<14147 13831 14332 13086 14646 14304>,
			<12408 13819 14097 12901 14198 14478>,
			<13920 13856 13864 12915 13683 14527>,
			<16707 14018 13660 12959 13216 14531>,
			<17174 14597 13776 12897 13160 14253>,
			<15209 16591 14796 12650 13308 13604>,
			<13411 17975 15881 12499 13408 13216>,
			<12918 17747 16703 12714 13249 13252>,
			<12557 17322 17419 13249 12992 13318>,
			<12417 17258 17630 14271 12985 13346>,
			<12336 17540 17664 16610 13320 13354>,
			<12225 17799 17701 18147 13858 13376>,
			<11981 17908 17953 18393 15287 14346>,
			<11603 18002 18311 18472 17075 15912>,
			<11289 17925 18410 18300 17351 16121>,
			<10993 17105 18387 17654 16828 15351>,
			<10815 16004 18358 17060 16218 14806>,
			<10905 14505 18270 16686 15599 14907>,
			<11125 12700 18079 16400 14984 15082>,
			<11201 12253 17903 16389 14751 14990>,
			<11193 12442 17679 16585 14638 14197>,
			<11186 12609 17402 16835 14591 13642>,
			<11251 12471 16922 17104 14844 13715>,
			<11414 12146 16383 17438 15377 13924>,
			<11476 12016 16311 17894 15862 14360>,
			<11461 11987 16628 18640 16406 15547>,
			<11436 11975 16897 19051 16699 16323>,
			<11404 12090 17023 18979 16644 16260>,
			<11362 12341 17171 18800 16503 16105>,
			<11329 12407 17170 18446 16258 15930>,
			<11269 12195 16962 17517 15628 15682>,
			<11218 11992 16723 16652 15161 15536>,
			<11266 12077 16475 16012 15081 15609>,
			<11431 12262 16188 15675 15085 15687>,
			<11581 12110 16052 16023 15286 15316>,
			<11744 11994 15457 16042 15929 14806>,
			<12012 12101 14641 15886 15136 14076>,
			<12110 12175 14983 14934 14443 15316>,
			<12235 12181 14567 14587 14577 15613>,
			<12331 12232 14290 14593 15255 15035>,
			<12420 12560 14344 15131 15434 14525>,
			<12409 12483 13280 15278 16336 14984>,
			<12119 12133 12438 16976 17005 17804>,
			<11796 11879 12111 17738 19604 18652>,
			<11212 11772 12025 18390 19765 20261>,
			<11212 11772 12025 18390 19765 20261>,
			<11212 11772 12025 18390 19765 20261>;
	};

	qcom,pc-temp-y6-lut {
		qcom,lut-col-legend = <(-10) 0 10 25 40 50>;
		qcom,lut-row-legend = <10000 9800 9600 9400 9200 9000>,
			<8800 8600 8400 8200 8000 7800>,
			<7600 7400 7200 7000 6800 6600>,
			<6400 6200 6000 5800 5600 5400>,
			<5200 5000 4800 4600 4400 4200>,
			<4000 3800 3600 3400 3200 3000>,
			<2800 2600 2400 2200 2000 1800>,
			<1600 1400 1200 1000 900 800>,
			<700 600 500 400 300 200>,
			<100 0>;
		qcom,lut-data = <7271 6083 5497 5149 5069 5051>,
			<7197 6094 5504 5147 5068 5050>,
			<7125 6099 5507 5145 5067 5049>,
			<7059 6099 5506 5145 5067 5049>,
			<7000 6095 5503 5145 5068 5050>,
			<6951 6090 5499 5145 5069 5051>,
			<6913 6078 5491 5146 5071 5052>,
			<6879 6058 5481 5147 5073 5054>,
			<6834 6039 5476 5149 5075 5056>,
			<6765 6017 5471 5151 5077 5058>,
			<6725 6005 5469 5154 5080 5061>,
			<6727 6019 5471 5158 5082 5063>,
			<6732 6043 5473 5162 5086 5066>,
			<6716 6039 5476 5167 5089 5069>,
			<6591 5975 5481 5173 5093 5072>,
			<6484 5917 5484 5180 5098 5075>,
			<6469 5900 5473 5190 5104 5079>,
			<6461 5889 5451 5199 5110 5084>,
			<6451 5876 5431 5200 5117 5090>,
			<6438 5858 5410 5198 5127 5099>,
			<6426 5841 5391 5194 5133 5104>,
			<6416 5828 5375 5172 5117 5092>,
			<6407 5816 5361 5139 5087 5070>,
			<6405 5804 5354 5127 5074 5058>,
			<6411 5791 5349 5122 5066 5051>,
			<6420 5783 5346 5120 5063 5048>,
			<6434 5786 5346 5121 5064 5049>,
			<6456 5797 5345 5123 5066 5052>,
			<6479 5810 5344 5125 5069 5055>,
			<6505 5833 5342 5129 5074 5058>,
			<6534 5861 5341 5133 5079 5062>,
			<6568 5892 5344 5138 5085 5067>,
			<6609 5929 5350 5142 5091 5072>,
			<6650 5970 5359 5145 5092 5075>,
			<6693 6015 5373 5148 5092 5077>,
			<6738 6064 5391 5149 5092 5077>,
			<6784 6117 5412 5146 5085 5070>,
			<6830 6175 5437 5140 5074 5058>,
			<6878 6237 5463 5138 5071 5056>,
			<6927 6304 5492 5137 5071 5057>,
			<6979 6374 5523 5137 5072 5058>,
			<7037 6444 5557 5139 5073 5058>,
			<7103 6518 5595 5142 5073 5058>,
			<7179 6599 5646 5144 5069 5053>,
			<7271 6693 5709 5146 5068 5051>,
			<7349 6746 5733 5149 5073 5058>,
			<7345 6764 5765 5158 5080 5066>,
			<7438 6842 5819 5172 5090 5078>,
			<7529 6926 5877 5191 5105 5092>,
			<7630 7010 5945 5206 5109 5086>,
			<7745 7072 5979 5187 5082 5063>,
			<7889 7158 6057 5198 5085 5067>,
			<8108 7318 6239 5228 5099 5076>,
			<8691 7518 6514 5284 5126 5106>,
			<8691 7518 6514 5284 5126 5106>,
			<8691 7518 6514 5284 5126 5106>;
	};

};
